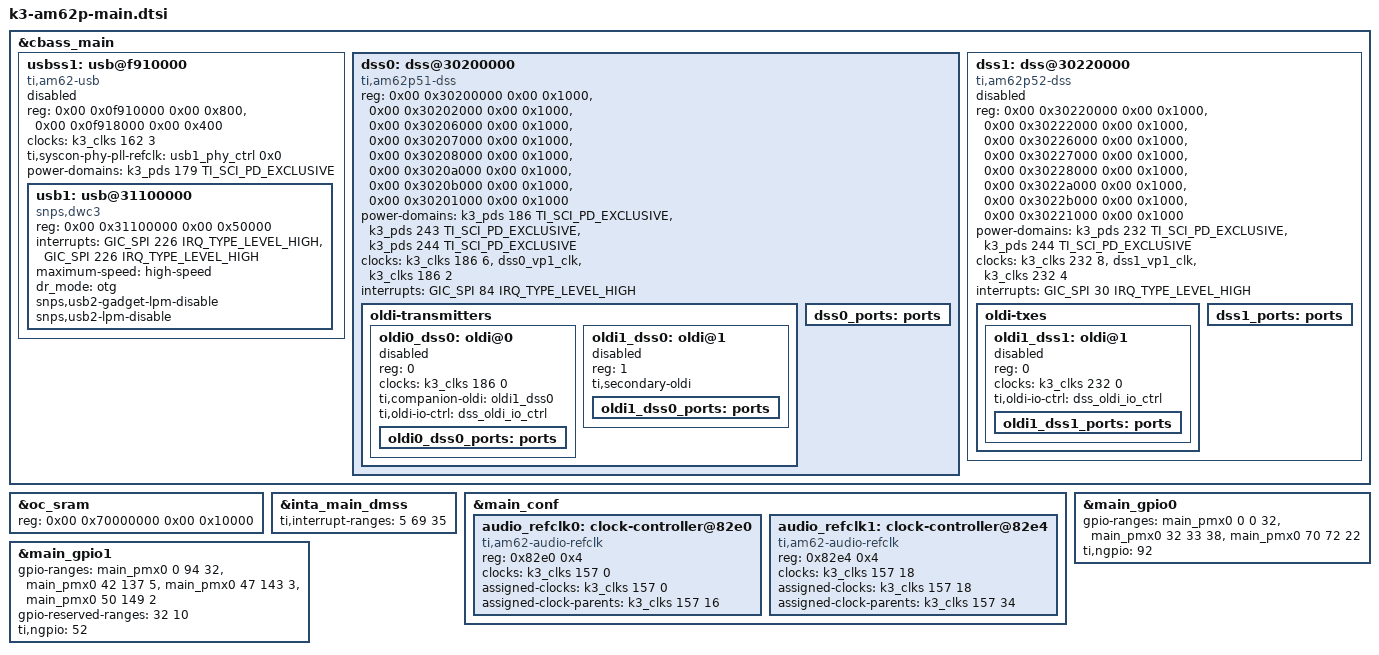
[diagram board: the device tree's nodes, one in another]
// SPDX-License-Identifier: GPL-2.0-only OR MIT
/*
 * Device Tree file for the AM62P MAIN domain peripherals
 *
 * Copyright (C) 2023-2024 Texas Instruments Incorporated - https://www.ti.com/
 */

&cbass_main {
	usbss1: usb@f910000 {
		compatible = "ti,am62-usb";
		reg = <0x00 0x0f910000 0x00 0x800>,
		      <0x00 0x0f918000 0x00 0x400>;
		clocks = <&k3_clks 162 3>;
		clock-names = "ref";
		ti,syscon-phy-pll-refclk = <&usb1_phy_ctrl 0x0>;
		#address-cells = <2>;
		#size-cells = <2>;
		power-domains = <&k3_pds 179 TI_SCI_PD_EXCLUSIVE>;
		ranges;
		status = "disabled";

		usb1: usb@31100000 {
			compatible = "snps,dwc3";
			reg = <0x00 0x31100000 0x00 0x50000>;
			interrupts = <GIC_SPI 226 IRQ_TYPE_LEVEL_HIGH>, /* irq.0 */
			<GIC_SPI 226 IRQ_TYPE_LEVEL_HIGH>; /* irq.0 */
			interrupt-names = "host", "peripheral";
			maximum-speed = "high-speed";
			dr_mode = "otg";
			snps,usb2-gadget-lpm-disable;
			snps,usb2-lpm-disable;
		};
	};

	dss0: dss@30200000 {
		compatible = "ti,am62p51-dss";
		reg = <0x00 0x30200000 0x00 0x1000>, /* common */
		      <0x00 0x30202000 0x00 0x1000>, /* vidl1 */
		      <0x00 0x30206000 0x00 0x1000>, /* vid */
		      <0x00 0x30207000 0x00 0x1000>, /* ovr1 */
		      <0x00 0x30208000 0x00 0x1000>, /* ovr2 */
		      <0x00 0x3020a000 0x00 0x1000>, /* vp1: Used for OLDI */
		      <0x00 0x3020b000 0x00 0x1000>, /* vp2: Used as DPI Out */
		      <0x00 0x30201000 0x00 0x1000>; /* common1 */
		reg-names = "common", "vidl1", "vid",
			    "ovr1", "ovr2", "vp1", "vp2", "common1";
		power-domains = <&k3_pds 186 TI_SCI_PD_EXCLUSIVE>,	/* DSS0 */
				<&k3_pds 243 TI_SCI_PD_EXCLUSIVE>,	/* OLDI0 */
				<&k3_pds 244 TI_SCI_PD_EXCLUSIVE>;	/* OLDI1 */
		clocks = <&k3_clks 186 6>,
			 <&dss0_vp1_clk>,
			 <&k3_clks 186 2>;
		clock-names = "fck", "vp1", "vp2";
		interrupts = <GIC_SPI 84 IRQ_TYPE_LEVEL_HIGH>;
		status = "okay";

		oldi-transmitters {
			bootph-all;
			status = "okay";
			#address-cells = <1>;
			#size-cells = <0>;

			oldi0_dss0: oldi@0 {
				reg = <0>;
				clocks = <&k3_clks 186 0>;
				clock-names = "serial";
				ti,companion-oldi = <&oldi1_dss0>;
				ti,oldi-io-ctrl = <&dss_oldi_io_ctrl>;
				status = "disabled";

				oldi0_dss0_ports: ports {
				};
			};

			oldi1_dss0: oldi@1 {
				reg = <1>;
				ti,secondary-oldi;
				status = "disabled";

				oldi1_dss0_ports: ports {
				};
			};
		};

		dss0_ports: ports {
			#address-cells = <1>;
			#size-cells = <0>;
		};
	};

	dss1: dss@30220000 {
		compatible = "ti,am62p52-dss";
		reg = <0x00 0x30220000 0x00 0x1000>, /* common */
		      <0x00 0x30222000 0x00 0x1000>, /* vidl1 */
		      <0x00 0x30226000 0x00 0x1000>, /* vid */
		      <0x00 0x30227000 0x00 0x1000>, /* ovr1 */
		      <0x00 0x30228000 0x00 0x1000>, /* ovr2 */
		      <0x00 0x3022a000 0x00 0x1000>, /* vp1: Used for OLDI */
		      <0x00 0x3022b000 0x00 0x1000>, /* vp2: Used as DPI Out */
		      <0x00 0x30221000 0x00 0x1000>; /* common1 */
		reg-names = "common", "vidl1", "vid",
			    "ovr1", "ovr2", "vp1", "vp2", "common1";
		power-domains = <&k3_pds 232 TI_SCI_PD_EXCLUSIVE>,	/* DSS0 */
				<&k3_pds 244 TI_SCI_PD_EXCLUSIVE>;	/* OLDI1 */
		clocks = <&k3_clks 232 8>,
			 <&dss1_vp1_clk>,
			 <&k3_clks 232 4>;
		clock-names = "fck", "vp1", "vp2";
		interrupts = <GIC_SPI 30 IRQ_TYPE_LEVEL_HIGH>;
		status = "disabled";

		oldi-txes {
			#address-cells = <1>;
			#size-cells = <0>;

			oldi1_dss1: oldi@1 {
				reg = <0>;
				clocks = <&k3_clks 232 0>;
				clock-names = "serial";
				ti,oldi-io-ctrl = <&dss_oldi_io_ctrl>;
				status = "disabled";

				oldi1_dss1_ports: ports {
				};
			};
		};

		dss1_ports: ports {
			#address-cells = <1>;
			#size-cells = <0>;
		};
	};
};

&oc_sram {
	reg = <0x00 0x70000000 0x00 0x10000>;
	ranges = <0x00 0x00 0x70000000 0x10000>;
};

&inta_main_dmss {
	ti,interrupt-ranges = <5 69 35>;
};

&main_conf {
	audio_refclk0: clock-controller@82e0 {
		compatible = "ti,am62-audio-refclk";
		reg = <0x82e0 0x4>;
		clocks = <&k3_clks 157 0>;
		assigned-clocks = <&k3_clks 157 0>;
		assigned-clock-parents = <&k3_clks 157 16>;
		#clock-cells = <0>;
	};

	audio_refclk1: clock-controller@82e4 {
		compatible = "ti,am62-audio-refclk";
		reg = <0x82e4 0x4>;
		clocks = <&k3_clks 157 18>;
		assigned-clocks = <&k3_clks 157 18>;
		assigned-clock-parents = <&k3_clks 157 34>;
		#clock-cells = <0>;
	};
};

&main_gpio0 {
	gpio-ranges = <&main_pmx0 0 0 32>, <&main_pmx0 32 33 38>,
			<&main_pmx0 70 72 22>;
	ti,ngpio = <92>;
};

&main_gpio1 {
	gpio-ranges = <&main_pmx0 0 94 32>, <&main_pmx0 42 137 5>,
			<&main_pmx0 47 143 3>, <&main_pmx0 50 149 2>;
	gpio-reserved-ranges = <32 10>;
	ti,ngpio = <52>;
};
